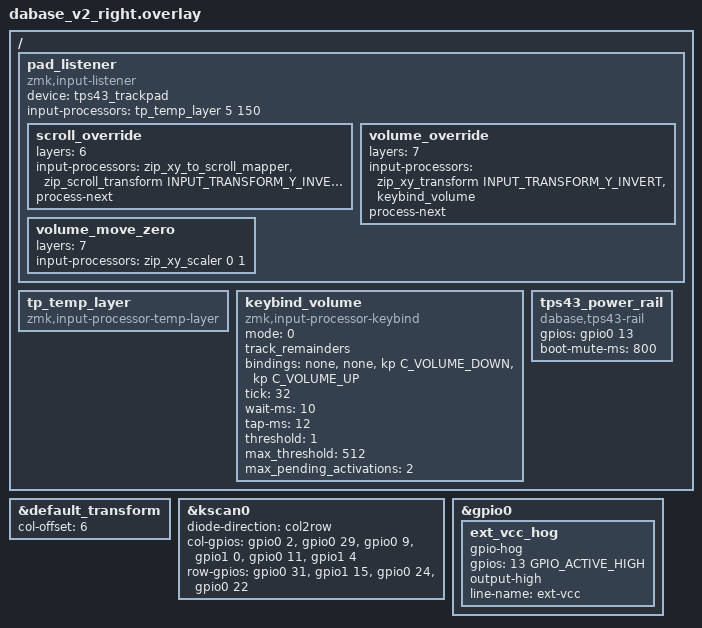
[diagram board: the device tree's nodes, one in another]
/*
 * Copyright (c) 2020 The ZMK Contributors
 *
 * SPDX-License-Identifier: MIT
 *
 * ble-azoteq-tps43: Azoteq TPS43 touchpad on the right half.
 * Replaces the direct PS/2 TrackPoint (Exp69..Exp82). See
 * dabase-v2-right-tps43.dtsi for wiring and driver notes.
 *
 * NOTE: shield .overlay files are NOT preprocessed with the Kconfig
 * symbols (an #ifdef CONFIG_ZMK_SPLIT_ROLE_CENTRAL here silently compiled
 * to the wrong branch and left the input listener disabled). The right
 * half is always the split central since Exp82, so this file configures
 * the pointer pipeline unconditionally.
 */

#include "dabase_v2.dtsi"
#include "dabase-v2-right-tps43.dtsi"
#include <behaviors.dtsi>

#include <input/processors.dtsi>
#include <dt-bindings/zmk/input_transform.h>
#include <dt-bindings/zmk/keys.h>

&default_transform {
    col-offset = <6>;
};

&kscan0 {
    diode-direction = "col2row";
    col-gpios
        = <&gpio0 2  GPIO_ACTIVE_HIGH>
        , <&gpio0 29 GPIO_ACTIVE_HIGH>
        , <&gpio0 9  GPIO_ACTIVE_HIGH>
        , <&gpio1 0  GPIO_ACTIVE_HIGH>
        , <&gpio0 11 GPIO_ACTIVE_HIGH>
        , <&gpio1 4  GPIO_ACTIVE_HIGH>
    ;

    row-gpios
        = <&gpio0 31 (GPIO_ACTIVE_HIGH | GPIO_PULL_DOWN)>
        , <&gpio1 15 (GPIO_ACTIVE_HIGH | GPIO_PULL_DOWN)>
        , <&gpio0 24 (GPIO_ACTIVE_HIGH | GPIO_PULL_DOWN)>
        , <&gpio0 22 (GPIO_ACTIVE_HIGH | GPIO_PULL_DOWN)>
    ;
};

/ {
    /* The right half is the split central, so the pad's own input device
     * feeds the HID pointer pipeline directly. */
    pad_listener: pad_listener {
        compatible = "zmk,input-listener";
        status = "okay";
        device = <&tps43_trackpad>;

        /* Touch the pad -> layer 5 (tp_layer) for MB1/MB2/MB3 on the right
         * thumb cluster. 150 ms idle timeout holds the layer through a
         * normal pause between touches. NB: the processor treats 0 as
         * "no auto-release" (layer sticks), so a non-zero timeout is used. */
        input-processors = <&tp_temp_layer 5 150>;

        scroll_override {
            layers = <6>;
            /* Hold J -> finger movement becomes scroll. 1:1: a trackpad
             * emits pixel-sized deltas, unlike the PS/2 TrackPoint's tiny
             * counts. */
            input-processors = <&zip_xy_to_scroll_mapper>, <&zip_scroll_transform INPUT_TRANSFORM_Y_INVERT>;
            process-next;
        };

        /* Hold K (layer 7) -> finger movement becomes volume: Y-invert so
         * up = louder. The keybind override runs first (process-next), then
         * volume_move_zero scales X/Y to 0 so the cursor stays put. */
        volume_override {
            layers = <7>;
            input-processors = <&zip_xy_transform INPUT_TRANSFORM_Y_INVERT>, <&keybind_volume>;
            process-next;
        };

        volume_move_zero {
            layers = <7>;
            input-processors = <&zip_xy_scaler 0 1>;
        };
    };

    tp_temp_layer: tp_temp_layer {
        compatible = "zmk,input-processor-temp-layer";
        #input-processor-cells = <2>;
        status = "okay";
    };

    /* Exp73: volume keybind - defined inline (the module's own dtsi pulls
     * <dt-bindings/zmk/input-processor-keybind.h>, missing from ZMK + the
     * module). Bindings order is [RIGHT, LEFT, DOWN, UP]: X mapped to
     * &none so only Y produces volume. tick 32 = very slow. */
    keybind_volume: keybind_volume {
        compatible = "zmk,input-processor-keybind";
        #input-processor-cells = <0>;
        mode = <0>;
        track_remainders;
        bindings = <&none>, <&none>, <&kp C_VOLUME_DOWN>, <&kp C_VOLUME_UP>;
        tick = <32>;
        wait-ms = <10>;
        tap-ms = <12>;
        threshold = <1>;
        max_threshold = <512>;
        max_pending_activations = <2>;
    };
};

/ {
    /* The pad is powered from the nice_nano EXT_VCC rail (P0.13), gated by
     * drivers/input/tps43_power_policy.c on ZMK's activity state. ZMK's own
     * ext_power driver is not used: it saves its state to settings on every
     * change, which left the rail persisted "off" in the PS/2 era. */
    /delete-node/ EXT_POWER;

    tps43_power_rail: tps43_power_rail {
        compatible = "dabase,tps43-rail";
        gpios = <&gpio0 13 GPIO_ACTIVE_HIGH>;
        boot-mute-ms = <800>;
    };
};

&gpio0 {
    /* Boot default: rail on before any driver probes (the policy takes the
     * level over at APPLICATION init). Without this the pad would be dark
     * during its own driver init. */
    ext_vcc_hog {
        gpio-hog;
        gpios = <13 GPIO_ACTIVE_HIGH>;
        output-high;
        line-name = "ext-vcc";
    };
};
